# STM32L443VCT6 register map
File version: 1.0
Registers are 32-bit, access not given, reset 0x0 unless marked. A register's access mark holds for its fields unless they carry their own. Offsets are from the block's base; [hi:lo] are bit positions; {n}, {i} and the like mark numbered series; 'fields as' and 'values as' point back to an identical list.

## SDMMC1
Base 0x40012800
0x00 POWER
  [1:0] PWRCTRL
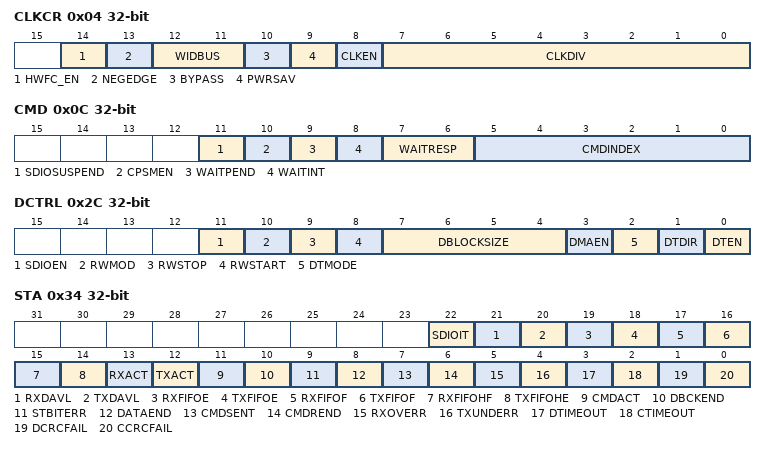
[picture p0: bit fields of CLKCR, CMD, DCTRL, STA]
0x04 CLKCR
  [14] HWFC_EN, [13] NEGEDGE, [12:11] WIDBUS, [10] BYPASS, [9] PWRSAV, [8] CLKEN, [7:0] CLKDIV
0x08 ARG
  [31:0] CMDARG
0x0C CMD
  [11] SDIOSUSPEND, [10] CPSMEN, [9] WAITPEND, [8] WAITINT, [7:6] WAITRESP, [5:0] CMDINDEX
0x10 RESPCMD
  [5:0] RESPCMD
{0x10+4i} RESP{i} (i=1..4)
  [31:0] CARDSTATUS{i}
0x24 DTIMER
  [31:0] DATATIME
0x28 DLEN
  [24:0] DATALENGTH
0x2C DCTRL
  [11] SDIOEN, [10] RWMOD, [9] RWSTOP, [8] RWSTART, [7:4] DBLOCKSIZE, [3] DMAEN, [2] DTMODE, [1] DTDIR, [0] DTEN
0x30 DCOUNT
  [24:0] DATACOUNT
0x34 STA
  [22] SDIOIT, [21] RXDAVL, [20] TXDAVL, [19] RXFIFOE, [18] TXFIFOE, [17] RXFIFOF, [16] TXFIFOF, [15] RXFIFOHF, [14] TXFIFOHE, [13] RXACT, [12] TXACT, [11] CMDACT, [10] DBCKEND, [9] STBITERR, [8] DATAEND, [7] CMDSENT, [6] CMDREND, [5] RXOVERR, [4] TXUNDERR, [3] DTIMEOUT, [2] CTIMEOUT, [1] DCRCFAIL, [0] CCRCFAIL
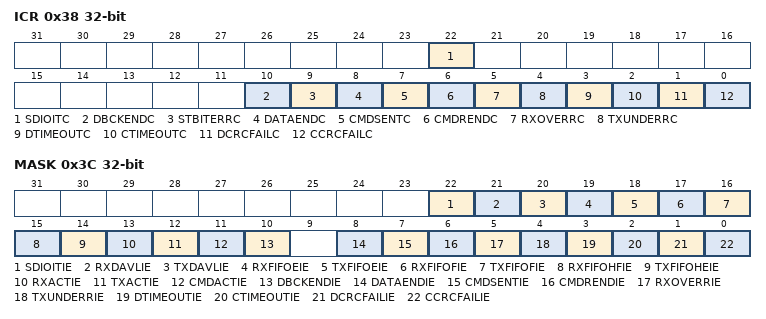
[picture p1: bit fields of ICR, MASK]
0x38 ICR
  [22] SDIOITC, [10] DBCKENDC, [9] STBITERRC, [8] DATAENDC, [7] CMDSENTC, [6] CMDRENDC, [5] RXOVERRC, [4] TXUNDERRC, [3] DTIMEOUTC, [2] CTIMEOUTC, [1] DCRCFAILC, [0] CCRCFAILC
0x3C MASK
  [22] SDIOITIE, [21] RXDAVLIE, [20] TXDAVLIE, [19] RXFIFOEIE, [18] TXFIFOEIE, [17] RXFIFOFIE, [16] TXFIFOFIE, [15] RXFIFOHFIE, [14] TXFIFOHEIE, [13] RXACTIE, [12] TXACTIE, [11] CMDACTIE, [10] DBCKENDIE, [8] DATAENDIE, [7] CMDSENTIE, [6] CMDRENDIE, [5] RXOVERRIE, [4] TXUNDERRIE, [3] DTIMEOUTIE, [2] CTIMEOUTIE, [1] DCRCFAILIE, [0] CCRCFAILIE
0x48 FIFOCNT
  [23:0] FIFOCOUNT
0x80 FIFO
  [31:0] FIFODATA

## SAI1
Base 0x40015400
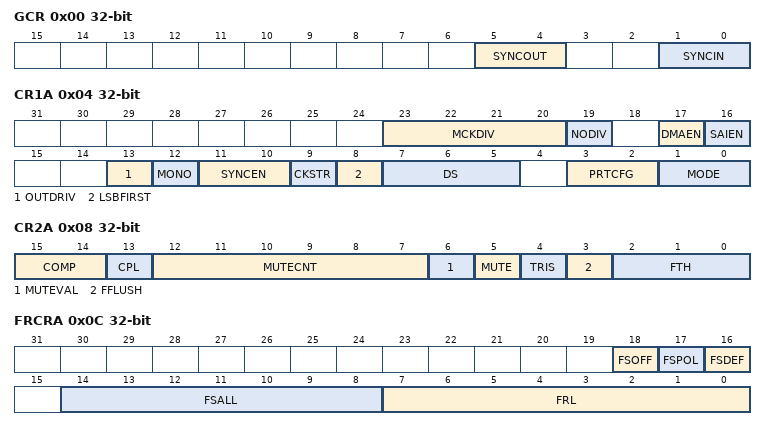
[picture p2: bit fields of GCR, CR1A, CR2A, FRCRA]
0x00 GCR
  [5:4] SYNCOUT, [1:0] SYNCIN
0x04 CR1A
  [23:20] MCKDIV, [19] NODIV, [17] DMAEN, [16] SAIEN, [13] OUTDRIV, [12] MONO, [11:10] SYNCEN, [9] CKSTR, [8] LSBFIRST, [7:5] DS, [3:2] PRTCFG, [1:0] MODE
0x08 CR2A
  [15:14] COMP, [13] CPL, [12:7] MUTECNT, [6] MUTEVAL, [5] MUTE, [4] TRIS, [3] FFLUSH, [2:0] FTH
0x0C FRCRA
  [18] FSOFF, [17] FSPOL, [16] FSDEF, [14:8] FSALL, [7:0] FRL
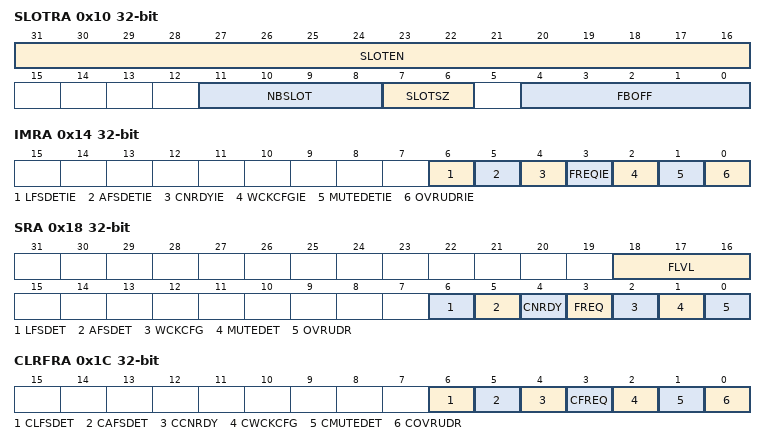
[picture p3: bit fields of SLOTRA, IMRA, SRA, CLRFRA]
0x10 SLOTRA
  [31:16] SLOTEN, [11:8] NBSLOT, [7:6] SLOTSZ, [4:0] FBOFF
0x14 IMRA
  [6] LFSDETIE, [5] AFSDETIE, [4] CNRDYIE, [3] FREQIE, [2] WCKCFGIE, [1] MUTEDETIE, [0] OVRUDRIE
0x18 SRA
  [18:16] FLVL, [6] LFSDET, [5] AFSDET, [4] CNRDY, [3] FREQ, [2] WCKCFG, [1] MUTEDET, [0] OVRUDR
0x1C CLRFRA
  [6] CLFSDET, [5] CAFSDET, [4] CCNRDY, [3] CFREQ, [2] CWCKCFG, [1] CMUTEDET, [0] COVRUDR
0x20 DRA
  [31:0] DATA
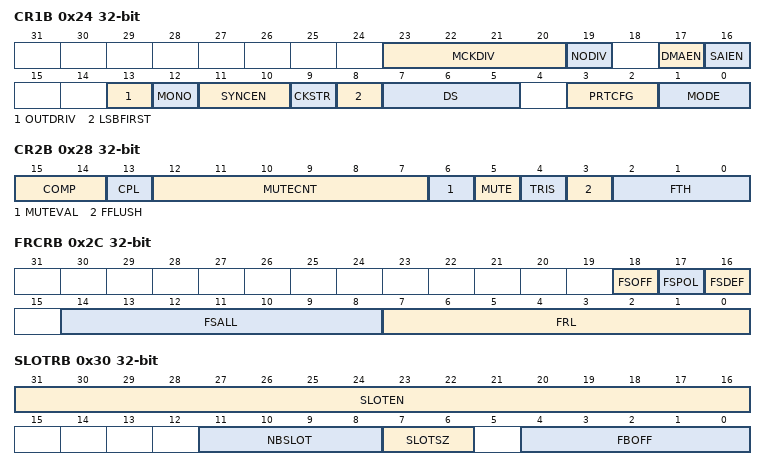
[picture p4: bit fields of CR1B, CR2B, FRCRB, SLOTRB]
0x24 CR1B
  fields as CR1A
0x28 CR2B
  fields as CR2A
0x2C FRCRB
  [18] FSOFF, [17] FSPOL, [16] FSDEF, [14:8] FSALL, [7:0] FRL
0x30 SLOTRB
  [31:16] SLOTEN, [11:8] NBSLOT, [7:6] SLOTSZ, [4:0] FBOFF
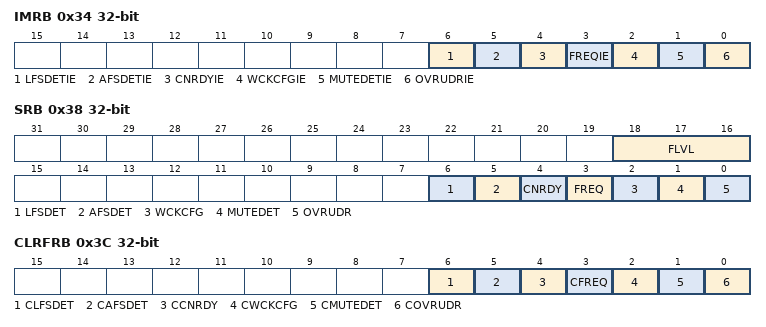
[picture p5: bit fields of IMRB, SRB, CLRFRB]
0x34 IMRB
  fields as IMRA
0x38 SRB
  fields as SRA
0x3C CLRFRB
  fields as CLRFRA
0x40 DRB
  [31:0] DATA

## DMA1
Base 0x40020000
Same registers: DMA2 0x40020400
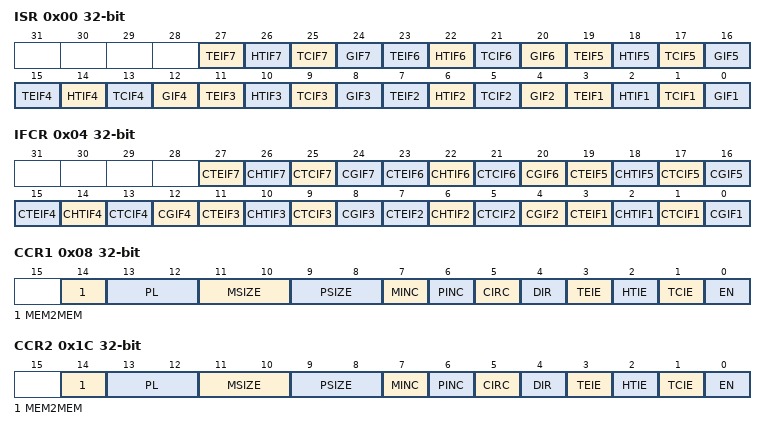
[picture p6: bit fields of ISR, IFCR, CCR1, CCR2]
0x00 ISR
  [4n-1] TEIF{n} (n=1..7), [4n-2] HTIF{n} (n=1..7), [4n-3] TCIF{n} (n=1..7), [4n-4] GIF{n} (n=1..7)
0x04 IFCR
  [4n-1] CTEIF{n} (n=1..7), [4n-2] CHTIF{n} (n=1..7), [4n-3] CTCIF{n} (n=1..7), [4n-4] CGIF{n} (n=1..7)
0x08 CCR1
  [14] MEM2MEM, [13:12] PL, [11:10] MSIZE, [9:8] PSIZE, [7] MINC, [6] PINC, [5] CIRC, [4] DIR, [3] TEIE, [2] HTIE, [1] TCIE, [0] EN
0x0C CNDTR1
  [15:0] NDT
0x10 CPAR1
  [31:0] PA
{0x0+0x14*i} CMAR{i} (i=1..7)
  [31:0] MA
0x1C CCR2
  fields as CCR1
0x20 CNDTR2
  [15:0] NDT
0x24 CPAR2
  [31:0] PA
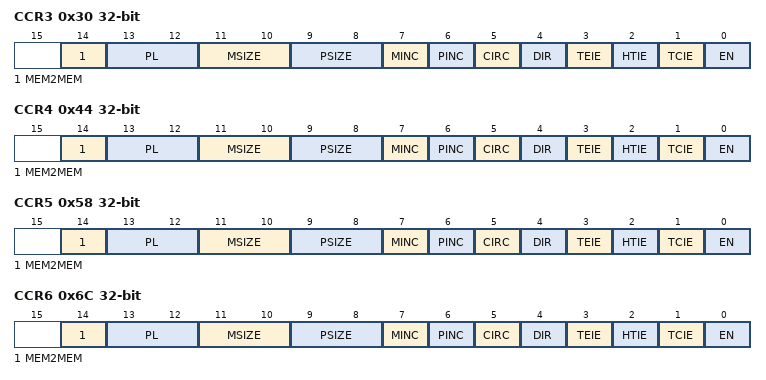
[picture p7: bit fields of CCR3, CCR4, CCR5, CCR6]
0x30 CCR3
  fields as CCR1
0x34 CNDTR3
  [15:0] NDT
0x38 CPAR3
  [31:0] PA
0x44 CCR4
  fields as CCR1
0x48 CNDTR4
  [15:0] NDT
0x4C CPAR4
  [31:0] PA
0x58 CCR5
  fields as CCR1
0x5C CNDTR5
  [15:0] NDT
0x60 CPAR5
  [31:0] PA
0x6C CCR6
  fields as CCR1
0x70 CNDTR6
  [15:0] NDT
0x74 CPAR6
  [31:0] PA
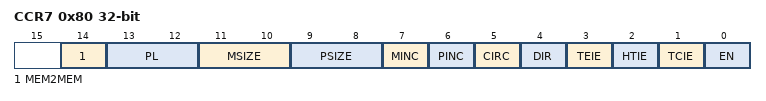
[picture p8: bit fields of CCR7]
0x80 CCR7
  fields as CCR1
0x84 CNDTR7
  [15:0] NDT
0x88 CPAR7
  [31:0] PA

## DMA1_CSELR
Base 0x400200A8
Same registers: DMA2_CSELR 0x400204A8
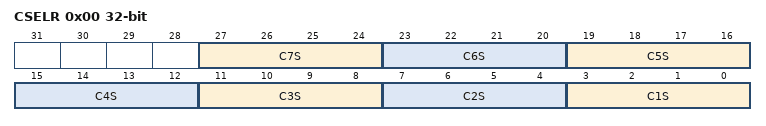
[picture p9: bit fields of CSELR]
0x00 CSELR
  [4n-1:4n-4] C{n}S (n=1..7)
